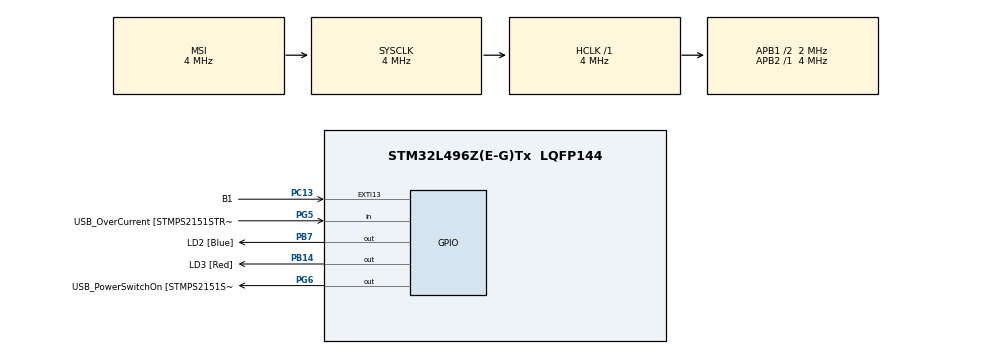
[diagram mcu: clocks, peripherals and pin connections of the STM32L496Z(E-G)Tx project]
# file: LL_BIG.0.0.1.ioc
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FREERTOS.Queues01=Consumer_Q,16,uint16_t,0,Dynamic,NULL,NULL
FREERTOS.Tasks01=defaultTask,0,128,StartDefaultTask,Default,NULL,Dynamic,NULL,NULL;Producer_TSK1,-3,256,StartProducer_TSK1,Default,NULL,Dynamic,NULL,NULL;Consumer_TSK1,-3,256,StartConsumer_TSK1,Default,NULL,Dynamic,NULL,NULL
FREERTOS.configTOTAL_HEAP_SIZE=16384
Mcu.Family=STM32L4
Mcu.Name=STM32L496Z(E-G)Tx
Mcu.Package=LQFP144
NVIC.PriorityGroup=NVIC_PRIORITYGROUP_4
NVIC.TIM6_DAC_IRQn=true\:0\:0\:false\:false\:true\:false\:false
NVIC.TimeBase=TIM6_DAC_IRQn
NVIC.TimeBaseIP=TIM6
PA10.GPIO_Label=USB_ID
PA10.Signal=USB_OTG_FS_ID
PA11.GPIO_Label=USB_DM
PA11.Signal=USB_OTG_FS_DM
PA12.GPIO_Label=USB_DP
PA12.Signal=USB_OTG_FS_DP
PA13\ (JTMS/SWDIO).GPIO_Label=TMS
PA13\ (JTMS/SWDIO).Mode=Trace_Asynchronous_SW
PA13\ (JTMS/SWDIO).Signal=SYS_JTMS-SWDIO
PA14\ (JTCK/SWCLK).GPIO_Label=TCK
PA14\ (JTCK/SWCLK).Mode=Trace_Asynchronous_SW
PA14\ (JTCK/SWCLK).Signal=SYS_JTCK-SWCLK
PA8.GPIO_Label=USB_SOF [TP1]
PA8.Signal=USB_OTG_FS_SOF
PA9.GPIO_Label=USB_VBUS
PA9.Signal=USB_OTG_FS_VBUS
PB14.GPIO_Label=LD3 [Red]
PB14.Signal=GPIO_Output
PB3\ (JTDO/TRACESWO).GPIO_Label=SWO
PB3\ (JTDO/TRACESWO).Mode=Trace_Asynchronous_SW
PB3\ (JTDO/TRACESWO).Signal=SYS_JTDO-SWO
PB7.GPIO_Label=LD2 [Blue]
PB7.Signal=GPIO_Output
PC13.GPIO_Label=B1
PC13.Signal=GPXTI13
PC14-OSC32_IN\ (PC14).Signal=RCC_OSC32_IN
PC15-OSC32_OUT\ (PC15).Signal=RCC_OSC32_OUT
PG5.GPIO_Label=USB_OverCurrent [STMPS2151STR_FAULT]
PG5.Signal=GPIO_Input
PG6.GPIO_Label=USB_PowerSwitchOn [STMPS2151STR_EN]
PG6.Signal=GPIO_Output
PG7.GPIO_Label=STLK_RX [STM32F103CBT6_PA3]
PG7.Signal=LPUART1_TX
PG8.GPIO_Label=STLK_TX [STM32F103CBT6_PA2]
PG8.Signal=LPUART1_RX
PH1-OSC_OUT\ (PH1).Signal=RCC_OSC_OUT
ProjectManager.HeapSize=0x200
ProjectManager.StackSize=0x400
ProjectManager.TargetToolchain=SW4STM32
RCC.48MHZClocksFreq_Value=24000000
RCC.AHBFreq_Value=4000000
RCC.APB1CLKDivider=RCC_HCLK_DIV2
RCC.APB1Freq_Value=2000000
RCC.APB1TimFreq_Value=4000000
RCC.APB2Freq_Value=4000000
RCC.APB2TimFreq_Value=4000000
RCC.CortexFreq_Value=4000000
RCC.HCLKFreq_Value=4000000
RCC.HSE_VALUE=8000000
RCC.HSI48_VALUE=48000000
RCC.HSI_VALUE=16000000
RCC.LSE_VALUE=32768
RCC.MSI_VALUE=4000000
RCC.PLLMUL=RCC_PLL_MUL9
RCC.PRESCALERUSB=RCC_USBCLKSOURCE_PLL_DIV1_5
RCC.SYSCLKFreq_VALUE=4000000
RCC.SYSCLKSourceVirtual=RCC_SYSCLKSOURCE_PLLCLK
RCC.USBFreq_Value=16000000
RCC.VCOOutputFreq_Value=32000000
VP_FREERTOS_VS_ENABLE.Mode=Enabled
VP_SYS_VS_tim6.Mode=TIM6
board=NUCLEO-L496ZG

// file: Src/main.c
/**
  ******************************************************************************
  * @file           : main.c
  * @brief          : Main program body
  ******************************************************************************
  * This notice applies to any and all portions of this file
  * that are not between comment pairs USER CODE BEGIN and
  * USER CODE END. Other portions of this file, whether
  * inserted by the user or by software development tools
  * are owned by their respective copyright owners.
  *
  * Copyright (c) 2018 STMicroelectronics International N.V.
  * All rights reserved.
  *
  * Redistribution and use in source and binary forms, with or without
  * modification, are permitted, provided that the following conditions are met:
  *
  * 1. Redistribution of source code must retain the above copyright notice,
  *    this list of conditions and the following disclaimer.
  * 2. Redistributions in binary form must reproduce the above copyright notice,
  *    this list of conditions and the following disclaimer in the documentation
  *    and/or other materials provided with the distribution.
  * 3. Neither the name of STMicroelectronics nor the names of other
  *    contributors to this software may be used to endorse or promote products
  *    derived from this software without specific written permission.
  * 4. This software, including modifications and/or derivative works of this
  *    software, must execute solely and exclusively on microcontroller or
  *    microprocessor devices manufactured by or for STMicroelectronics.
  * 5. Redistribution and use of this software other than as permitted under
  *    this license is void and will automatically terminate your rights under
  *    this license.
  *
  * THIS SOFTWARE IS PROVIDED BY STMICROELECTRONICS AND CONTRIBUTORS "AS IS"
  * AND ANY EXPRESS, IMPLIED OR STATUTORY WARRANTIES, INCLUDING, BUT NOT
  * LIMITED TO, THE IMPLIED WARRANTIES OF MERCHANTABILITY, FITNESS FOR A
  * PARTICULAR PURPOSE AND NON-INFRINGEMENT OF THIRD PARTY INTELLECTUAL PROPERTY
  * RIGHTS ARE DISCLAIMED TO THE FULLEST EXTENT PERMITTED BY LAW. IN NO EVENT
  * SHALL STMICROELECTRONICS OR CONTRIBUTORS BE LIABLE FOR ANY DIRECT, INDIRECT,
  * INCIDENTAL, SPECIAL, EXEMPLARY, OR CONSEQUENTIAL DAMAGES (INCLUDING, BUT NOT
  * LIMITED TO, PROCUREMENT OF SUBSTITUTE GOODS OR SERVICES; LOSS OF USE, DATA,
  * OR PROFITS; OR BUSINESS INTERRUPTION) HOWEVER CAUSED AND ON ANY THEORY OF
  * LIABILITY, WHETHER IN CONTRACT, STRICT LIABILITY, OR TORT (INCLUDING
  * NEGLIGENCE OR OTHERWISE) ARISING IN ANY WAY OUT OF THE USE OF THIS SOFTWARE,
  * EVEN IF ADVISED OF THE POSSIBILITY OF SUCH DAMAGE.
  *
  ******************************************************************************
  */
#include "main.h"
#include "stm32l4xx_hal.h"
#include "cmsis_os.h"
#include "gpio.h"

/* USER CODE BEGIN PV */
/* Private variables ---------------------------------------------------------*/

/* USER CODE END PV */

void SystemClock_Config(void);
void MX_FREERTOS_Init(void);

/* USER CODE BEGIN PFP */
/* Private function prototypes -----------------------------------------------*/

/* USER CODE END PFP */

int main(void)
{

  /* MCU Configuration----------------------------------------------------------*/

  /* Reset of all peripherals, Initializes the Flash interface and the Systick. */
  HAL_Init();

  /* Configure the system clock */
  SystemClock_Config();

  /* Initialize all configured peripherals */
  MX_GPIO_Init();

  /* Call init function for freertos objects (in freertos.c) */
  MX_FREERTOS_Init();

  /* Start scheduler */
  osKernelStart();

  /* We should never get here as control is now taken by the scheduler */

  /* Infinite loop */
  while (1)
  {

  }

}

void SystemClock_Config(void)
{

  RCC_OscInitTypeDef RCC_OscInitStruct;
  RCC_ClkInitTypeDef RCC_ClkInitStruct;

    /**Initializes the CPU, AHB and APB busses clocks
    */
  RCC_OscInitStruct.OscillatorType = RCC_OSCILLATORTYPE_MSI;
  RCC_OscInitStruct.MSIState = RCC_MSI_ON;
  RCC_OscInitStruct.MSICalibrationValue = 0;
  RCC_OscInitStruct.MSIClockRange = RCC_MSIRANGE_6;
  RCC_OscInitStruct.PLL.PLLState = RCC_PLL_NONE;
  if (HAL_RCC_OscConfig(&RCC_OscInitStruct) != HAL_OK)
  {
    _Error_Handler(__FILE__, __LINE__);
  }

    /**Initializes the CPU, AHB and APB busses clocks
    */
  RCC_ClkInitStruct.ClockType = RCC_CLOCKTYPE_HCLK|RCC_CLOCKTYPE_SYSCLK
                              |RCC_CLOCKTYPE_PCLK1|RCC_CLOCKTYPE_PCLK2;
  RCC_ClkInitStruct.SYSCLKSource = RCC_SYSCLKSOURCE_MSI;
  RCC_ClkInitStruct.AHBCLKDivider = RCC_SYSCLK_DIV1;
  RCC_ClkInitStruct.APB1CLKDivider = RCC_HCLK_DIV2;
  RCC_ClkInitStruct.APB2CLKDivider = RCC_HCLK_DIV1;

  if (HAL_RCC_ClockConfig(&RCC_ClkInitStruct, FLASH_LATENCY_0) != HAL_OK)
  {
    _Error_Handler(__FILE__, __LINE__);
  }

    /**Configure the main internal regulator output voltage
    */
  if (HAL_PWREx_ControlVoltageScaling(PWR_REGULATOR_VOLTAGE_SCALE1) != HAL_OK)
  {
    _Error_Handler(__FILE__, __LINE__);
  }

    /**Configure the Systick interrupt time
    */
  HAL_SYSTICK_Config(HAL_RCC_GetHCLKFreq()/1000);

    /**Configure the Systick
    */
  HAL_SYSTICK_CLKSourceConfig(SYSTICK_CLKSOURCE_HCLK);

  /* SysTick_IRQn interrupt configuration */
  HAL_NVIC_SetPriority(SysTick_IRQn, 15, 0);
}

void HAL_TIM_PeriodElapsedCallback(TIM_HandleTypeDef *htim)
{
  if (htim->Instance == TIM6) {
    HAL_IncTick();
  }
}

void _Error_Handler(char *file, int line)
{
  while(1)
  {
  }
}

/************************ (C) COPYRIGHT STMicroelectronics *****END OF FILE****/

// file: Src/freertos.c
/* USER CODE BEGIN Header */
/**
  ******************************************************************************
  * File Name          : freertos.c
  * Description        : Code for freertos applications
  ******************************************************************************
  * This notice applies to any and all portions of this file
  * that are not between comment pairs USER CODE BEGIN and
  * USER CODE END. Other portions of this file, whether
  * inserted by the user or by software development tools
  * are owned by their respective copyright owners.
  *
  * Copyright (c) 2018 STMicroelectronics International N.V.
  * All rights reserved.
  *
  * Redistribution and use in source and binary forms, with or without
  * modification, are permitted, provided that the following conditions are met:
  *
  * 1. Redistribution of source code must retain the above copyright notice,
  *    this list of conditions and the following disclaimer.
  * 2. Redistributions in binary form must reproduce the above copyright notice,
  *    this list of conditions and the following disclaimer in the documentation
  *    and/or other materials provided with the distribution.
  * 3. Neither the name of STMicroelectronics nor the names of other
  *    contributors to this software may be used to endorse or promote products
  *    derived from this software without specific written permission.
  * 4. This software, including modifications and/or derivative works of this
  *    software, must execute solely and exclusively on microcontroller or
  *    microprocessor devices manufactured by or for STMicroelectronics.
  * 5. Redistribution and use of this software other than as permitted under
  *    this license is void and will automatically terminate your rights under
  *    this license.
  *
  * THIS SOFTWARE IS PROVIDED BY STMICROELECTRONICS AND CONTRIBUTORS "AS IS"
  * AND ANY EXPRESS, IMPLIED OR STATUTORY WARRANTIES, INCLUDING, BUT NOT
  * LIMITED TO, THE IMPLIED WARRANTIES OF MERCHANTABILITY, FITNESS FOR A
  * PARTICULAR PURPOSE AND NON-INFRINGEMENT OF THIRD PARTY INTELLECTUAL PROPERTY
  * RIGHTS ARE DISCLAIMED TO THE FULLEST EXTENT PERMITTED BY LAW. IN NO EVENT
  * SHALL STMICROELECTRONICS OR CONTRIBUTORS BE LIABLE FOR ANY DIRECT, INDIRECT,
  * INCIDENTAL, SPECIAL, EXEMPLARY, OR CONSEQUENTIAL DAMAGES (INCLUDING, BUT NOT
  * LIMITED TO, PROCUREMENT OF SUBSTITUTE GOODS OR SERVICES; LOSS OF USE, DATA,
  * OR PROFITS; OR BUSINESS INTERRUPTION) HOWEVER CAUSED AND ON ANY THEORY OF
  * LIABILITY, WHETHER IN CONTRACT, STRICT LIABILITY, OR TORT (INCLUDING
  * NEGLIGENCE OR OTHERWISE) ARISING IN ANY WAY OUT OF THE USE OF THIS SOFTWARE,
  * EVEN IF ADVISED OF THE POSSIBILITY OF SUCH DAMAGE.
  *
  ******************************************************************************
  */
/* USER CODE END Header */

#include "FreeRTOS.h"
#include "task.h"
#include "main.h"
#include "cmsis_os.h"

/* USER CODE BEGIN Includes */
#include "stm32l4xx_hal.h"
/* USER CODE END Includes */

osThreadId defaultTaskHandle;
osThreadId Producer_TSK1Handle;
osThreadId Consumer_TSK1Handle;
osMessageQId Consumer_QHandle;

void StartDefaultTask(void const * argument);
void StartProducer_TSK1(void const * argument);
void StartConsumer_TSK1(void const * argument);

void MX_FREERTOS_Init(void); /* (MISRA C 2004 rule 8.1) */

void MX_FREERTOS_Init(void) {

  /* Create the thread(s) */
  /* definition and creation of defaultTask */
  osThreadDef(defaultTask, StartDefaultTask, osPriorityNormal, 0, 128);
  defaultTaskHandle = osThreadCreate(osThread(defaultTask), NULL);

  /* definition and creation of Producer_TSK1 */
  osThreadDef(Producer_TSK1, StartProducer_TSK1, osPriorityIdle, 0, 256);
  Producer_TSK1Handle = osThreadCreate(osThread(Producer_TSK1), NULL);

  /* definition and creation of Consumer_TSK1 */
  osThreadDef(Consumer_TSK1, StartConsumer_TSK1, osPriorityIdle, 0, 256);
  Consumer_TSK1Handle = osThreadCreate(osThread(Consumer_TSK1), NULL);

  /* Create the queue(s) */
  /* definition and creation of Consumer_Q */
/* what about the sizeof here??? cd native code */
  osMessageQDef(Consumer_Q, 16, uint16_t);
  Consumer_QHandle = osMessageCreate(osMessageQ(Consumer_Q), NULL);

}

void StartDefaultTask(void const * argument)
{

  /* USER CODE BEGIN StartDefaultTask */
  /* Infinite loop */
  for(;;)
  {
	  //osDelay(1000);
	  // HAL_GPIO_TogglePin( LD4_GPIO_Port, LD4_Pin );
	  osDelay(400);
	  // Pin in Reset mode swithc on LED
	  HAL_GPIO_WritePin( LD3_GPIO_Port, LD3_Pin, GPIO_PIN_RESET );
	  osDelay(600);
	  // Pin in Set mode switch off LED4
	  HAL_GPIO_WritePin( LD3_GPIO_Port, LD3_Pin, GPIO_PIN_SET );
  }
  /* USER CODE END StartDefaultTask */
}

void StartProducer_TSK1(void const * argument)
{
  for(;;)
  {
    osDelay(1);
  }
}

void StartConsumer_TSK1(void const * argument)
{
  for(;;)
  {
    osDelay(1);
  }
}

/************************ (C) COPYRIGHT STMicroelectronics *****END OF FILE****/
